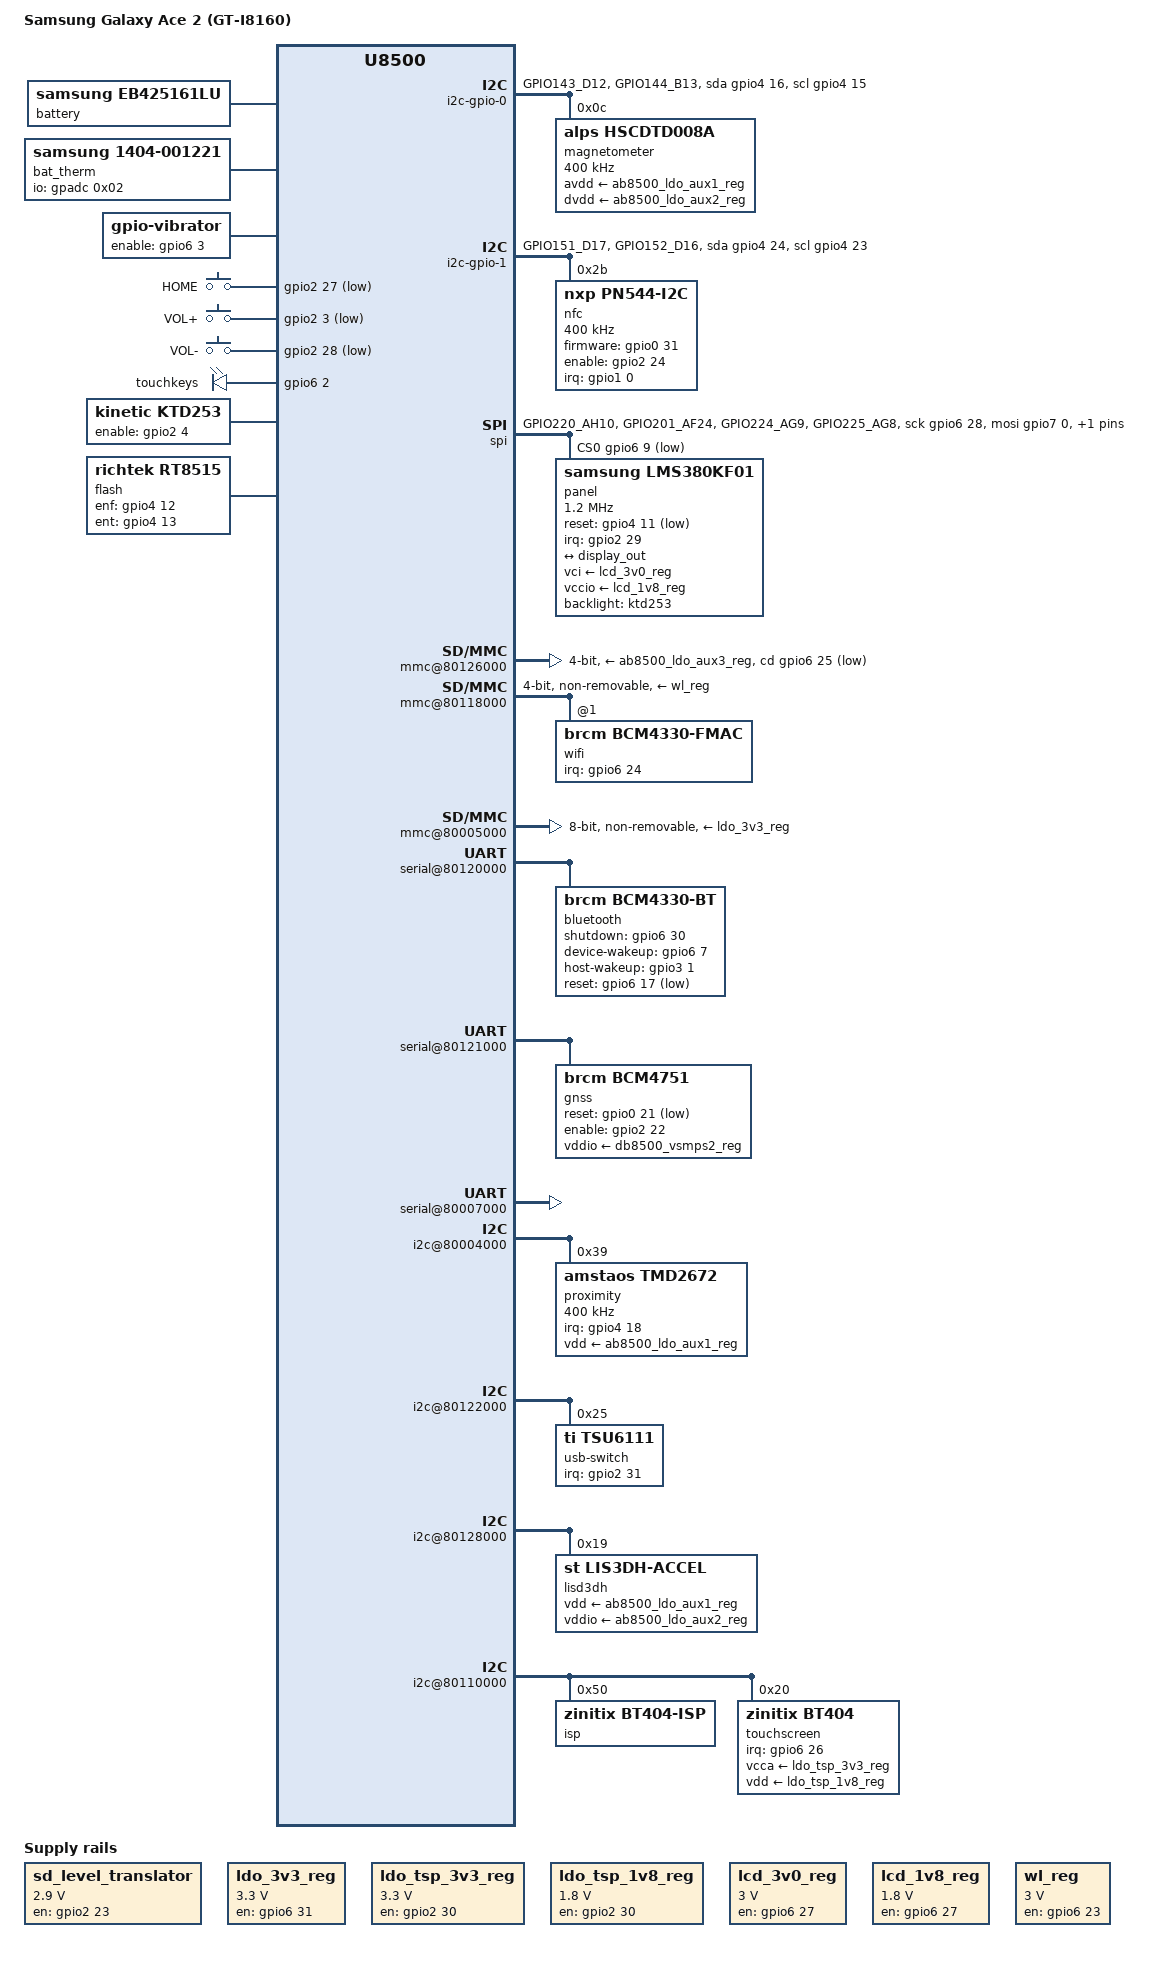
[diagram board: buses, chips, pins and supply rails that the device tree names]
/dts-v1/;
#include "ste-db8500.dtsi"
#include "ste-ab8500.dtsi"
#include "ste-dbx5x0-pinctrl.dtsi"
#include <dt-bindings/gpio/gpio.h>
#include <dt-bindings/leds/common.h>
#include <dt-bindings/input/input.h>
#include <dt-bindings/interrupt-controller/irq.h>
/ {
	model = "Samsung Galaxy Ace 2 (GT-I8160)";
	compatible = "samsung,codina", "st-ericsson,u8500";
	cpus {
		cpu@300 {
			operating-points = <798720 0
					    399360 0
					    199680 0>;
		};
	};
	chosen {
		stdout-path = &serial2;
	};
	battery: battery {
		compatible = "samsung,eb425161lu";
	};
	thermal-zones {
		battery-thermal {
			polling-delay = <0>;
			polling-delay-passive = <0>;
			thermal-sensors = <&bat_therm>;
			trips {
				battery-crit-hi {
					temperature = <70000>;
					hysteresis = <2000>;
					type = "critical";
				};
			};
		};
	};
	bat_therm: thermistor {
		compatible = "samsung,1404-001221";
		io-channels = <&gpadc 0x02>;  
		pullup-uv = <1800000>;
		pullup-ohm = <230000>;
		pulldown-ohm = <0>;
		#thermal-sensor-cells = <0>;
	};
	sd_level_translator: regulator-gpio {
		compatible = "regulator-fixed";
		gpios = <&gpio2 23 GPIO_ACTIVE_HIGH>;
		enable-active-high;
		regulator-name = "sd-level-translator";
		regulator-min-microvolt = <2900000>;
		regulator-max-microvolt = <2900000>;
		regulator-type = "voltage";
		startup-delay-us = <200>;
		pinctrl-names = "default";
		pinctrl-0 = <&sd_level_translator_default>;
	};
	ldo_3v3_reg: regulator-gpio-ldo-3v3 {
		compatible = "regulator-fixed";
		regulator-name = "VMEM_3V3";
		regulator-min-microvolt = <3300000>;
		regulator-max-microvolt = <3300000>;
		gpios = <&gpio6 31 GPIO_ACTIVE_HIGH>;
		startup-delay-us = <5000>;
		enable-active-high;
		pinctrl-names = "default";
		pinctrl-0 = <&emmc_ldo_en_default_mode>;
	};
	ldo_tsp_3v3_reg: regulator-gpio-tsp-ldo-3v3 {
		compatible = "regulator-fixed";
		regulator-name = "LDO_TSP_A3V3";
		regulator-min-microvolt = <3300000>;
		regulator-max-microvolt = <3300000>;
		gpio = <&gpio2 30 GPIO_ACTIVE_HIGH>;
		startup-delay-us = <70000>;
		enable-active-high;
		pinctrl-names = "default";
		pinctrl-0 = <&tsp_ldo_en_default_mode>;
	};
	ldo_tsp_1v8_reg: regulator-gpio-tsp-ldo-1v8 {
		compatible = "regulator-fixed";
		regulator-name = "VREG_TSP_1V8";
		regulator-min-microvolt = <1800000>;
		regulator-max-microvolt = <1800000>;
		gpio = <&gpio2 30 GPIO_ACTIVE_HIGH>;
		startup-delay-us = <70000>;
		enable-active-high;
		pinctrl-names = "default";
		pinctrl-0 = <&tsp_ldo_en_default_mode>;
	};
	lcd_3v0_reg: regulator-gpio-lcd-3v0 {
		compatible = "regulator-fixed";
		regulator-name = "VREG_LCD_3.0V";
		regulator-min-microvolt = <3000000>;
		regulator-max-microvolt = <3000000>;
		gpio = <&gpio6 27 GPIO_ACTIVE_HIGH>;
		enable-active-high;
		pinctrl-names = "default";
		pinctrl-0 = <&lcd_pwr_en_default_mode>;
	};
	lcd_1v8_reg: regulator-gpio-lcd-1v8 {
		compatible = "regulator-fixed";
		regulator-name = "VREG_LCD_1.8V";
		regulator-min-microvolt = <1800000>;
		regulator-max-microvolt = <1800000>;
		gpio = <&gpio6 27 GPIO_ACTIVE_HIGH>;
		enable-active-high;
		pinctrl-names = "default";
		pinctrl-0 = <&lcd_pwr_en_default_mode>;
	};
	wl_reg: regulator-gpio-wlan {
		compatible = "regulator-fixed";
		regulator-name = "WL_REG_ON";
		regulator-min-microvolt = <3000000>;
		regulator-max-microvolt = <3000000>;
		startup-delay-us = <100000>;
		gpio = <&gpio6 23 GPIO_ACTIVE_HIGH>;
		enable-active-high;
		pinctrl-names = "default";
		pinctrl-0 = <&wlan_ldo_en_default>;
	};
	vibrator {
		compatible = "gpio-vibrator";
		enable-gpios = <&gpio6 3 GPIO_ACTIVE_HIGH>;
		pinctrl-names = "default";
		pinctrl-0 = <&vibrator_default>;
	};
	gpio-keys {
		compatible = "gpio-keys";
		pinctrl-names = "default";
		pinctrl-0 = <&gpio_keys_default_mode>;
		button-home {
			linux,code = <KEY_HOME>;
			label = "HOME";
			gpios = <&gpio2 27 GPIO_ACTIVE_LOW>;
		};
		button-volup {
			linux,code = <KEY_VOLUMEUP>;
			label = "VOL+";
			gpios = <&gpio2 3 GPIO_ACTIVE_LOW>;
		};
		button-voldown {
			linux,code = <KEY_VOLUMEDOWN>;
			label = "VOL-";
			gpios = <&gpio2 28 GPIO_ACTIVE_LOW>;
		};
	};
	gpio-leds {
		compatible = "gpio-leds";
		pinctrl-names = "default";
		pinctrl-0 = <&gpio_leds_default_mode>;
		touchkey-led {
			label = "touchkeys";
			gpios = <&gpio6 2 GPIO_ACTIVE_HIGH>;
			default-state = "on";
		};
	};
	ktd253: backlight {
		compatible = "kinetic,ktd253";
		enable-gpios = <&gpio2 4 GPIO_ACTIVE_HIGH>;
		default-brightness = <13>;
		pinctrl-names = "default";
		pinctrl-0 = <&ktd253_backlight_default_mode>;
	};
	flash {
		compatible = "richtek,rt8515";
		enf-gpios = <&gpio4 12 GPIO_ACTIVE_HIGH>;
		ent-gpios = <&gpio4 13 GPIO_ACTIVE_HIGH>;
		richtek,rfs-ohms = <16000>;
		richtek,rts-ohms = <100000>;
		pinctrl-names = "default";
		pinctrl-0 = <&gpio_flash_default_mode>;
		led {
			function = LED_FUNCTION_FLASH;
			color = <LED_COLOR_ID_WHITE>;
			flash-max-timeout-us = <250000>;
			flash-max-microamp = <343750>;
			led-max-microamp = <55000>;
		};
	};
	i2c-gpio-0 {
		compatible = "i2c-gpio";
		sda-gpios = <&gpio4 16 (GPIO_ACTIVE_HIGH|GPIO_OPEN_DRAIN)>;
		scl-gpios = <&gpio4 15 (GPIO_ACTIVE_HIGH|GPIO_OPEN_DRAIN)>;
		pinctrl-names = "default";
		pinctrl-0 = <&i2c_gpio_0_default>;
		#address-cells = <1>;
		#size-cells = <0>;
		magnetometer@c {
			compatible = "alps,hscdtd008a";
			reg = <0x0c>;
			clock-frequency = <400000>;
			avdd-supply = <&ab8500_ldo_aux1_reg>;  
			dvdd-supply = <&ab8500_ldo_aux2_reg>;  
		};
	};
	i2c-gpio-1 {
		compatible = "i2c-gpio";
		sda-gpios = <&gpio4 24 (GPIO_ACTIVE_HIGH|GPIO_OPEN_DRAIN)>;
		scl-gpios = <&gpio4 23 (GPIO_ACTIVE_HIGH|GPIO_OPEN_DRAIN)>;
		pinctrl-names = "default";
		pinctrl-0 = <&i2c_gpio_1_default>;
		#address-cells = <1>;
		#size-cells = <0>;
		nfc@2b {
			compatible = "nxp,pn544-i2c";
			reg = <0x2b>;
			clock-frequency = <400000>;
			interrupt-parent = <&gpio1>;
			interrupts = <0 IRQ_TYPE_EDGE_FALLING>;
			firmware-gpios = <&gpio0 31 GPIO_ACTIVE_HIGH>;
			enable-gpios = <&gpio2 24 GPIO_ACTIVE_HIGH>;
			pinctrl-names = "default";
			pinctrl-0 = <&pn544_codina_default>;
		};
	};
	spi {
		compatible = "spi-gpio";
		sck-gpios = <&gpio6 28 GPIO_ACTIVE_HIGH>;
		mosi-gpios = <&gpio7 0 GPIO_ACTIVE_HIGH>;
		miso-gpios = <&gpio7 1 GPIO_ACTIVE_HIGH>;
		cs-gpios = <&gpio6 9 GPIO_ACTIVE_LOW>;
		num-chipselects = <1>;
		pinctrl-names = "default";
		pinctrl-0 = <&spi_gpio_0_default>;
		#address-cells = <1>;
		#size-cells = <0>;
		panel@0 {
			compatible = "samsung,lms380kf01";
			spi-max-frequency = <1200000>;
			spi-cpha;
			spi-cpol;
			reg = <0>;
			vci-supply = <&lcd_3v0_reg>;
			vccio-supply = <&lcd_1v8_reg>;
			reset-gpios = <&gpio4 11 GPIO_ACTIVE_LOW>;
			interrupt-parent = <&gpio2>;
			interrupts = <29 IRQ_TYPE_EDGE_RISING>;
			pinctrl-names = "default";
			pinctrl-0 = <&panel_default_mode>;
			backlight = <&ktd253>;
			port {
				panel_in: endpoint {
					remote-endpoint = <&display_out>;
				};
			};
		};
	};
	soc {
		mmc@80126000 {
			arm,primecell-periphid = <0x10480180>;
			max-frequency = <100000000>;
			bus-width = <4>;
			cap-sd-highspeed;
			cap-mmc-highspeed;
			st,sig-pin-fbclk;
			full-pwr-cycle;
			vmmc-supply = <&ab8500_ldo_aux3_reg>;
			vqmmc-supply = <&sd_level_translator>;
			pinctrl-names = "default", "sleep";
			pinctrl-0 = <&mc0_a_2_default>;
			pinctrl-1 = <&mc0_a_2_sleep>;
			cd-gpios  = <&gpio6 25 GPIO_ACTIVE_LOW>;  
			status = "okay";
		};
		mmc@80118000 {
			arm,primecell-periphid = <0x10480180>;
			max-frequency = <50000000>;
			bus-width = <4>;
			non-removable;
			cap-sd-highspeed;
			pinctrl-names = "default", "sleep";
			pinctrl-0 = <&mc1_a_2_default>;
			pinctrl-1 = <&mc1_a_2_sleep>;
			vmmc-supply = <&wl_reg>;
			#address-cells = <1>;
			#size-cells = <0>;
			status = "okay";
			wifi@1 {
				compatible = "brcm,bcm4330-fmac", "brcm,bcm4329-fmac";
				reg = <1>;
				interrupt-parent = <&gpio6>;
				interrupts = <24 IRQ_TYPE_EDGE_FALLING>;
				interrupt-names = "host-wake";
				pinctrl-names = "default";
				pinctrl-0 = <&wlan_default_mode>;
			};
		};
		mmc@80005000 {
			arm,primecell-periphid = <0x10480180>;
			max-frequency = <100000000>;
			bus-width = <8>;
			non-removable;
			cap-mmc-highspeed;
			mmc-ddr-1_8v;
			no-sdio;
			no-sd;
			vmmc-supply = <&ldo_3v3_reg>;
			pinctrl-names = "default", "sleep";
			pinctrl-0 = <&mc2_a_1_default>;
			pinctrl-1 = <&mc2_a_1_sleep>;
			status = "okay";
		};
		serial@80120000 {
			pinctrl-names = "default", "sleep";
			pinctrl-0 = <&u0_a_1_default>;
			pinctrl-1 = <&u0_a_1_sleep>;
			status = "okay";
			bluetooth {
				compatible = "brcm,bcm4330-bt";
				shutdown-gpios = <&gpio6 30 GPIO_ACTIVE_HIGH>;
				device-wakeup-gpios = <&gpio6 7 GPIO_ACTIVE_HIGH>;
				host-wakeup-gpios = <&gpio3 1 GPIO_ACTIVE_HIGH>;
				reset-gpios = <&gpio6 17 GPIO_ACTIVE_LOW>;
				pinctrl-names = "default";
				pinctrl-0 = <&bluetooth_default_mode>;
			};
		};
		serial@80121000 {
			status = "okay";
			pinctrl-names = "default", "sleep";
			pinctrl-0 = <&u1rxtx_a_1_default &u1ctsrts_a_1_default>;
			pinctrl-1 = <&u1rxtx_a_1_sleep &u1ctsrts_a_1_sleep>;
			gnss {
				compatible = "brcm,bcm4751";
				reset-gpios = <&gpio0 21 GPIO_ACTIVE_LOW>;
				enable-gpios = <&gpio2 22 GPIO_ACTIVE_HIGH>;
				vddio-supply = <&db8500_vsmps2_reg>;
				pinctrl-names = "default";
				pinctrl-0 = <&bcm4751_codina_default>;
			};
		};
		serial@80007000 {
			status = "okay";
			pinctrl-names = "default", "sleep";
			pinctrl-0 = <&u2rxtx_c_1_default>;
			pinctrl-1 = <&u2rxtx_c_1_sleep>;
		};
		prcmu@80157000 {
			ab8500 {
				phy {
					pinctrl-names = "default", "sleep";
					pinctrl-0 = <&usb_a_1_default>;
					pinctrl-1 = <&usb_a_1_sleep>;
				};
				ab8500_fg {
					line-impedance-micro-ohms = <36000>;
				};
				regulator {
					ab8500_ldo_aux1 {
						regulator-name = "V-SENSORS-VDD";
						regulator-min-microvolt = <3000000>;
						regulator-max-microvolt = <3000000>;
					};
					ab8500_ldo_aux2 {
						regulator-name = "V-SENSORS-VIO";
						regulator-min-microvolt = <1800000>;
						regulator-max-microvolt = <1800000>;
					};
					ab8500_ldo_aux3 {
						regulator-name = "V-MMC-SD";
						regulator-min-microvolt = <1200000>;
						regulator-max-microvolt = <2910000>;
					};
				};
			};
		};
		i2c@80004000 {
			status = "okay";
			pinctrl-names = "default", "sleep";
			pinctrl-0 = <&i2c0_a_1_default>;
			pinctrl-1 = <&i2c0_a_1_sleep>;
			proximity@39 {
				compatible = "amstaos,tmd2672";
				clock-frequency = <400000>;
				reg = <0x39>;
				interrupt-parent = <&gpio4>;
				interrupts = <18 IRQ_TYPE_EDGE_FALLING>;
				vdd-supply = <&ab8500_ldo_aux1_reg>;
				pinctrl-names = "default";
				pinctrl-0 = <&tms2672_codina_default>;
			};
		};
		i2c@80122000 {
			status = "okay";
			pinctrl-names = "default","sleep";
			pinctrl-0 = <&i2c1_b_2_default>;
			pinctrl-1 = <&i2c1_b_2_sleep>;
			usb-switch@25 {
				compatible = "ti,tsu6111";
				reg = <0x25>;
				interrupt-parent = <&gpio2>;
				interrupts = <31 IRQ_TYPE_EDGE_FALLING>;
				pinctrl-names = "default";
				pinctrl-0 = <&tsu6111_codina_default>;
			};
		};
		i2c@80128000 {
			status = "okay";
			pinctrl-names = "default", "sleep";
			pinctrl-0 = <&i2c2_b_2_default>;
			pinctrl-1 = <&i2c2_b_2_sleep>;
			lisd3dh@19 {
				compatible = "st,lis3dh-accel";
				st,drdy-int-pin = <1>;
				reg = <0x19>;
				vdd-supply = <&ab8500_ldo_aux1_reg>;  
				vddio-supply = <&ab8500_ldo_aux2_reg>;  
				mount-matrix = "0", "1", "0",
					       "-1", "0", "0",
					       "0", "0", "1";
			};
		};
		i2c@80110000 {
			status = "okay";
			pinctrl-names = "default", "sleep";
			pinctrl-0 = <&i2c3_c_2_default>;
			pinctrl-1 = <&i2c3_c_2_sleep>;
			isp@50 {
				compatible = "zinitix,bt404-isp";
				reg = <0x50>;
				pinctrl-names = "default";
				pinctrl-0 = <&tsp_default>;
			};
			touchscreen@20 {
				compatible = "zinitix,bt404";
				reg = <0x20>;
				interrupt-parent = <&gpio6>;
				interrupts = <26 IRQ_TYPE_EDGE_FALLING>;
				vcca-supply = <&ldo_tsp_3v3_reg>;
				vdd-supply = <&ldo_tsp_1v8_reg>;
				zinitix,mode = <2>;
				touchscreen-size-x = <480>;
				touchscreen-size-y = <800>;
				pinctrl-names = "default";
				pinctrl-0 = <&tsp_default>;
			};
		};
		mcde@a0350000 {
			status = "okay";
			pinctrl-names = "default";
			pinctrl-0 = <&dpi_default_mode>;
			port {
				display_out: endpoint {
					remote-endpoint = <&panel_in>;
				};
			};
		};
	};
};
&pinctrl {
	sdi0 {
		mc0_a_2_default {
			default_cfg4 {
				pins = "GPIO217_AH12";  
				ste,config = <&gpio_in_pd>;
			};
		};
	};
	sdi2 {
		mc2_a_1_default {
			default_cfg2 {
				pins = "GPIO130_C8";  
				ste,config = <&in_nopull>;
			};
		};
	};
	sd-level-translator {
		sd_level_translator_default: sd_level_translator_default {
			codina_cfg1 {
				pins = "GPIO87_B3";
				ste,config = <&gpio_out_hi>;
			};
		};
	};
	emmc-ldo {
		emmc_ldo_en_default_mode: emmc_ldo_default {
			codina_cfg1 {
				pins = "GPIO223_AH9";
				ste,config = <&gpio_out_hi>;
			};
		};
	};
	panel {
		panel_default_mode: panel_default {
			codina_cfg1 {
				pins = "GPIO139_C9";
				ste,config = <&gpio_out_lo>;
			};
			codina_cfg2 {
				pins = "GPIO93_B7";
				ste,config = <&gpio_in_nopull>;
			};
		};
	};
	tsp-ldo {
		tsp_ldo_en_default_mode: tsp_ldo_default {
			gavini_cfg1 {
				pins = "GPIO94_D7";
				ste,config = <&gpio_out_hi>;
			};
		};
	};
	lcd-ldo {
		lcd_pwr_en_default_mode: lcd_pwr_en_default {
			codina_cfg1 {
				pins = "GPIO219_AG10";
				ste,config = <&gpio_out_hi>;
			};
		};
	};
	key-led {
		gpio_leds_default_mode: en_led_ldo_default {
			codina_cfg1 {
				pins = "GPIO194_AF27";
				ste,config = <&gpio_out_hi>;
			};
		};
	};
	wlan-ldo {
		wlan_ldo_en_default: wlan_ldo_default {
			codina_cfg1 {
				pins = "GPIO215_AH13";
				ste,config = <&gpio_out_lo>;
			};
		};
	};
	backlight {
		ktd253_backlight_default_mode: backlight_default {
			skomer_cfg1 {
				pins = "GPIO68_E1";  
				ste,config = <&gpio_out_lo>;
			};
		};
	};
	flash {
		gpio_flash_default_mode: flash_default {
			codina_cfg1 {
				pins = "GPIO140_B11", "GPIO141_C12";
				ste,config = <&gpio_out_lo>;
			};
		};
	};
	gpio-keys {
		gpio_keys_default_mode: gpio_keys_default {
			skomer_cfg1 {
				pins = "GPIO67_G2",  
				       "GPIO91_B6",  
				       "GPIO92_D6";  
				ste,config = <&gpio_in_pu>;
			};
		};
	};
	tsp {
		tsp_default: tsp_default {
			codina_cfg1 {
				pins = "GPIO218_AH11";	 
				ste,config = <&gpio_in_nopull>;
			};
		};
	};
	tms2672 {
		tms2672_codina_default: tms2672_codina {
			codina_cfg1 {
				pins = "GPIO146_D13";
				ste,config = <&gpio_in_nopull>;
			};
		};
	};
	i2c-gpio-0 {
		i2c_gpio_0_default: i2c_gpio_0 {
			codina_cfg1 {
				pins = "GPIO143_D12", "GPIO144_B13";
				ste,config = <&gpio_in_nopull>;
			};
		};
	};
	i2c-gpio-1 {
		i2c_gpio_1_default: i2c_gpio_1 {
			codina_cfg1 {
				pins = "GPIO151_D17", "GPIO152_D16";
				ste,config = <&gpio_in_nopull>;
			};
		};
	};
	spi-gpio-0 {
		spi_gpio_0_default: spi_gpio_0_d {
			codina_cfg1 {
				pins = "GPIO220_AH10", "GPIO201_AF24", "GPIO224_AG9";
				ste,config = <&gpio_out_hi>;
			};
			codina_cfg2 {
				pins = "GPIO225_AG8";
				ste,config = <&gpio_in_pd>;
			};
		};
		spi_gpio_0_sleep: spi_gpio_0_s {
			codina_cfg1 {
				pins = "GPIO220_AH10", "GPIO201_AF24",
				       "GPIO224_AG9", "GPIO225_AG8";
				ste,config = <&gpio_out_hi>;
			};
		};
	};
	wlan {
		wlan_default_mode: wlan_default {
			codina_cfg2 {
				pins = "GPIO216_AG12";
				ste,config = <&gpio_in_pd>;
			};
		};
	};
	bluetooth {
		bluetooth_default_mode: bluetooth_default {
			codina_cfg1 {
				pins = "GPIO199_AH23", "GPIO222_AJ9";
				ste,config = <&gpio_out_lo>;
			};
			codina_cfg2 {
				pins = "GPIO97_D9";
				ste,config = <&gpio_in_nopull>;
			};
			codina_cfg3 {
				pins = "GPIO209_AG15";
				ste,config = <&gpio_out_hi>;
			};
		};
	};
	tsu6111 {
		tsu6111_codina_default: tsu6111_codina {
			codina_cfg1 {
				pins = "GPIO95_E8";
				ste,config = <&gpio_in_nopull>;
			};
		};
	};
	nfc {
		pn544_codina_default: pn544_codina {
			codina_cfg1 {
				pins = "GPIO32_V2";
				ste,config = <&gpio_in_nopull>;
			};
			codina_cfg2 {
				pins = "GPIO31_V3", "GPIO88_C4";
				ste,config = <&gpio_out_lo>;
			};
		};
	};
	bcm4751 {
		bcm4751_codina_default: bcm4751_codina {
			codina_cfg1 {
				pins = "GPIO21_AB3";
				ste,config = <&gpio_out_lo>;
			};
			codina_cfg2 {
				pins = "GPIO86_C6";
				ste,config = <&gpio_out_lo>;
			};
		};
	};
	vibrator {
		vibrator_default: vibrator_default {
			codina_cfg1 {
				pins = "GPIO195_AG28";	 
				ste,config = <&gpio_out_lo>;
			};
		};
	};
	mcde {
		dpi_default_mode: dpi_default {
			default_mux1 {
				function = "lcd";
				groups =
					"lcd_d0_d7_a_1",
					"lcd_d8_d11_a_1",
					"lcd_d12_d15_a_1",
					"lcd_d16_d23_b_1";
			};
			default_mux2 {
				function = "lcda";
				groups = "lcdaclk_b_1", "lcda_b_1";
			};
			default_cfg1 {
				pins = "GPIO150_C14", "GPIO169_D22", "GPIO170_C23", "GPIO171_D23";
				ste,config = <&in_nopull>;
			};
		};
	};
};
